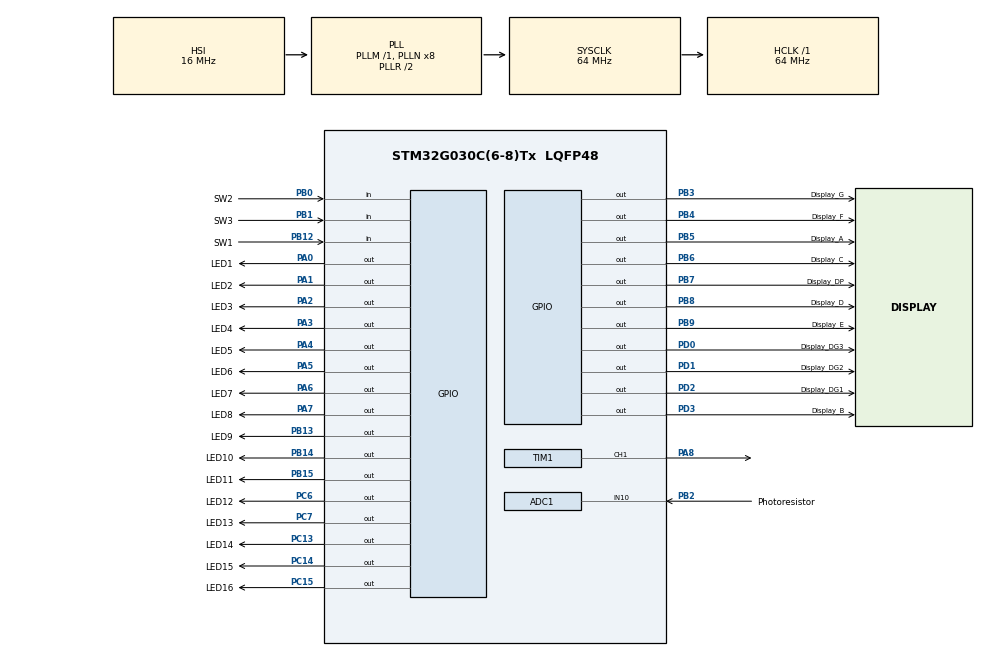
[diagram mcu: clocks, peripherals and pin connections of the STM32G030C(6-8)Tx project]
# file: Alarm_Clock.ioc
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ADC1.Channel-0\#ChannelRegularConversion=ADC_CHANNEL_10
ADC1.NbrOfConversionFlag=1
ADC1.Rank-0\#ChannelRegularConversion=1
ADC1.SamplingTime-0\#ChannelRegularConversion=ADC_SAMPLINGTIME_COMMON_1
ADC1.SelectedChannel=ADC_CHANNEL_VREFINT|ADC_CHANNEL_10
ADC1.master=1
Mcu.Family=STM32G0
Mcu.Name=STM32G030C(6-8)Tx
Mcu.Package=LQFP48
NVIC.TIM16_IRQn=true\:2\:0\:true\:false\:true\:true\:true\:true
NVIC.TIM1_BRK_UP_TRG_COM_IRQn=true\:0\:0\:false\:false\:true\:true\:true\:true
NVIC.TIM1_CC_IRQn=true\:0\:0\:false\:false\:true\:true\:true\:true
NVIC.TIM3_IRQn=true\:1\:0\:true\:false\:true\:true\:true\:true
PA0.GPIO_Label=LED1
PA0.Signal=GPIO_Output
PA1.GPIO_Label=LED2
PA1.Signal=GPIO_Output
PA13.Mode=Serial_Wire
PA13.Signal=SYS_SWDIO
PA14-BOOT0.Mode=Serial_Wire
PA14-BOOT0.Signal=SYS_SWCLK
PA2.GPIO_Label=LED3
PA2.Signal=GPIO_Output
PA3.GPIO_Label=LED4
PA3.Signal=GPIO_Output
PA4.GPIO_Label=LED5
PA4.Signal=GPIO_Output
PA5.GPIO_Label=LED6
PA5.Signal=GPIO_Output
PA6.GPIO_Label=LED7
PA6.Signal=GPIO_Output
PA7.GPIO_Label=LED8
PA7.Signal=GPIO_Output
PA8.Signal=S_TIM1_CH1
PB0.GPIO_Label=SW2
PB0.Signal=GPIO_Input
PB1.GPIO_Label=SW3
PB1.Signal=GPIO_Input
PB12.GPIO_Label=SW1
PB12.Signal=GPIO_Input
PB13.GPIO_Label=LED9
PB13.Signal=GPIO_Output
PB14.GPIO_Label=LED10
PB14.Signal=GPIO_Output
PB15.GPIO_Label=LED11
PB15.Signal=GPIO_Output
PB2.GPIO_Label=Photoresistor
PB2.Mode=IN10
PB2.Signal=ADC1_IN10
PB3.GPIO_Label=Display_G
PB3.Signal=GPIO_Output
PB4.GPIO_Label=Display_F
PB4.Signal=GPIO_Output
PB5.GPIO_Label=Display_A
PB5.Signal=GPIO_Output
PB6.GPIO_Label=Display_C
PB6.Signal=GPIO_Output
PB7.GPIO_Label=Display_DP
PB7.Signal=GPIO_Output
PB8.GPIO_Label=Display_D
PB8.Signal=GPIO_Output
PB9.GPIO_Label=Display_E
PB9.Signal=GPIO_Output
PC13.GPIO_Label=LED14
PC13.Signal=GPIO_Output
PC14-OSC32_IN\ (PC14).GPIO_Label=LED15
PC14-OSC32_IN\ (PC14).Signal=GPIO_Output
PC15-OSC32_OUT\ (PC15).GPIO_Label=LED16
PC15-OSC32_OUT\ (PC15).Signal=GPIO_Output
PC6.GPIO_Label=LED12
PC6.Signal=GPIO_Output
PC7.GPIO_Label=LED13
PC7.Signal=GPIO_Output
PD0.GPIO_Label=Display_DG3
PD0.Signal=GPIO_Output
PD1.GPIO_Label=Display_DG2
PD1.Signal=GPIO_Output
PD2.GPIO_Label=Display_DG1
PD2.Signal=GPIO_Output
PD3.GPIO_Label=Display_B
PD3.Signal=GPIO_Output
PF0-OSC_IN\ (PF0).Mode=HSE-External-Oscillator
PF0-OSC_IN\ (PF0).Signal=RCC_OSC_IN
PF1-OSC_OUT\ (PF1).Mode=HSE-External-Oscillator
PF1-OSC_OUT\ (PF1).Signal=RCC_OSC_OUT
ProjectManager.HeapSize=0x200
ProjectManager.StackSize=0x400
ProjectManager.TargetToolchain=MDK-ARM V5.32
RCC.ADCFreq_Value=64000000
RCC.AHBFreq_Value=64000000
RCC.CortexFreq_Value=64000000
RCC.EXTERNAL_CLOCK_VALUE=12288000
RCC.FLatency=FLASH_LATENCY_2
RCC.HCLKFreq_Value=64000000
RCC.HSE_VALUE=8000000
RCC.HSI_VALUE=16000000
RCC.LSE_VALUE=32768
RCC.SYSCLKFreq_VALUE=64000000
RCC.SYSCLKSource=RCC_SYSCLKSOURCE_PLLCLK
RCC.VCOOutputFreq_Value=128000000
SH.S_TIM1_CH1.0=TIM1_CH1,PWM Generation1 CH1
TIM1.AutoReloadPreload=TIM_AUTORELOAD_PRELOAD_ENABLE
TIM1.Channel-PWM\ Generation1\ CH1=TIM_CHANNEL_1
TIM1.Period=65535
TIM1.Prescaler=7
TIM1.Pulse-PWM\ Generation1\ CH1=0
TIM16.Period=99
TIM16.Prescaler=6399
TIM3.Period=999
TIM3.Prescaler=63
VP_ADC1_Vref_Input.Mode=IN-Vrefint
VP_TIM16_VS_ClockSourceINT.Mode=Enable_Timer
VP_TIM3_VS_ClockSourceINT.Mode=Internal
board=custom

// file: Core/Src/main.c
/* USER CODE BEGIN Header */
/**
  ******************************************************************************
  * @file           : main.c
  * @brief          : Main program body
  ******************************************************************************
  * @attention
  *
  * Copyright (c) 2024 STMicroelectronics.
  * All rights reserved.
  *
  * This software is licensed under terms that can be found in the LICENSE file
  * in the root directory of this software component.
  * If no LICENSE file comes with this software, it is provided AS-IS.
  *
  ******************************************************************************
  */
/* USER CODE END Header */
#include "main.h"
#include "adc.h"
#include "tim.h"
#include "gpio.h"

/* USER CODE BEGIN Includes */
#include "test.h"

/* USER CODE END Includes */

void SystemClock_Config(void);

int main(void)
{

  /* MCU Configuration--------------------------------------------------------*/

  /* Reset of all peripherals, Initializes the Flash interface and the Systick. */
  HAL_Init();

  /* Configure the system clock */
  SystemClock_Config();

  /* Initialize all configured peripherals */
  MX_GPIO_Init();
  MX_ADC1_Init();
  MX_TIM3_Init();
  MX_TIM1_Init();
  MX_TIM16_Init();
  /* USER CODE BEGIN 2 */
	Setup();
  /* USER CODE END 2 */

  /* Infinite loop */
  /* USER CODE BEGIN WHILE */
  while (1)
  {
		Loop();

    /* USER CODE END WHILE */

  }
}

void SystemClock_Config(void)
{
  RCC_OscInitTypeDef RCC_OscInitStruct = {0};
  RCC_ClkInitTypeDef RCC_ClkInitStruct = {0};

  /** Configure the main internal regulator output voltage
  */
  HAL_PWREx_ControlVoltageScaling(PWR_REGULATOR_VOLTAGE_SCALE1);

  /** Initializes the RCC Oscillators according to the specified parameters
  * in the RCC_OscInitTypeDef structure.
  */
  RCC_OscInitStruct.OscillatorType = RCC_OSCILLATORTYPE_HSI;
  RCC_OscInitStruct.HSIState = RCC_HSI_ON;
  RCC_OscInitStruct.HSIDiv = RCC_HSI_DIV1;
  RCC_OscInitStruct.HSICalibrationValue = RCC_HSICALIBRATION_DEFAULT;
  RCC_OscInitStruct.PLL.PLLState = RCC_PLL_ON;
  RCC_OscInitStruct.PLL.PLLSource = RCC_PLLSOURCE_HSI;
  RCC_OscInitStruct.PLL.PLLM = RCC_PLLM_DIV1;
  RCC_OscInitStruct.PLL.PLLN = 8;
  RCC_OscInitStruct.PLL.PLLP = RCC_PLLP_DIV2;
  RCC_OscInitStruct.PLL.PLLR = RCC_PLLR_DIV2;
  if (HAL_RCC_OscConfig(&RCC_OscInitStruct) != HAL_OK)
  {
    Error_Handler();
  }

  /** Initializes the CPU, AHB and APB buses clocks
  */
  RCC_ClkInitStruct.ClockType = RCC_CLOCKTYPE_HCLK|RCC_CLOCKTYPE_SYSCLK
                              |RCC_CLOCKTYPE_PCLK1;
  RCC_ClkInitStruct.SYSCLKSource = RCC_SYSCLKSOURCE_PLLCLK;
  RCC_ClkInitStruct.AHBCLKDivider = RCC_SYSCLK_DIV1;
  RCC_ClkInitStruct.APB1CLKDivider = RCC_HCLK_DIV1;

  if (HAL_RCC_ClockConfig(&RCC_ClkInitStruct, FLASH_LATENCY_2) != HAL_OK)
  {
    Error_Handler();
  }
}

void Error_Handler(void)
{
  __disable_irq();
  while (1)
  {
  }
}
